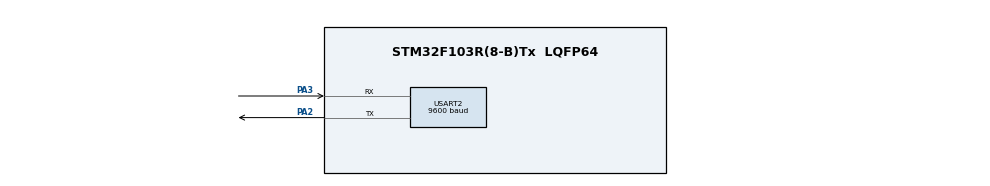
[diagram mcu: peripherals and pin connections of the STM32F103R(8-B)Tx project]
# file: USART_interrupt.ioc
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Mcu.Family=STM32F1
RCC.APB2Freq_Value=8000000
Mcu.Name=STM32F103R(8-B)Tx
PA2.Signal=USART2_TX
VP_SYS_VS_ND.Mode=No_Debug
NVIC.USART2_IRQn=true\:0\:0\:false\:false\:true\:true\:true
USART2.BaudRate=9600
Mcu.Package=LQFP64
ProjectManager.StackSize=0x400
USART2.VirtualMode=VM_ASYNC
PA3.Mode=Asynchronous
ProjectManager.HeapSize=0x200
ProjectManager.TargetToolchain=STM32CubeIDE
NVIC.PriorityGroup=NVIC_PRIORITYGROUP_4
PA2.Mode=Asynchronous
RCC.APB1Freq_Value=8000000
PA3.Signal=USART2_RX
board=custom

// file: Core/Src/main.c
/* USER CODE BEGIN Header */
/**
  ******************************************************************************
  * @file           : main.c
  * @brief          : Main program body
  ******************************************************************************
  * @attention
  *
  * <h2><center>&copy; Copyright (c) 2021 STMicroelectronics.
  * All rights reserved.</center></h2>
  *
  * This software component is licensed by ST under BSD 3-Clause license,
  * the "License"; You may not use this file except in compliance with the
  * License. You may obtain a copy of the License at:
  *                        opensource.org/licenses/BSD-3-Clause
  *
  ******************************************************************************
  */
/* USER CODE END Header */
#include "main.h"
#include "usart.h"
#include "gpio.h"

void SystemClock_Config(void);

/* USER CODE BEGIN 0 */
uint8_t rx_data = 0;

int _write(int file, char *ptr, int len)
{
	HAL_UART_Transmit(&huart2, (uint8_t *)ptr, (uint16_t)len, 0xFFFFFFFF);
	return (len);
}

int _read(int file, char *ptr, int len)
{
	HAL_UART_Receive(&huart2, (uint8_t *)ptr++, 1, 0xFFFFFFFF);
	return (1);
}

void HAL_UART_RxCpltCallback(UART_HandleTypeDef *huart)
{
	printf("rx data is %0x\r\n", rx_data);
	HAL_UART_Receive_IT(&huart2, &rx_data, 1);
}
/* USER CODE END 0 */

int main(void)
{

  /* MCU Configuration--------------------------------------------------------*/

  /* Reset of all peripherals, Initializes the Flash interface and the Systick. */
  HAL_Init();

  /* Configure the system clock */
  SystemClock_Config();

  /* Initialize all configured peripherals */
  MX_GPIO_Init();
  MX_USART2_UART_Init();
  /* USER CODE BEGIN 2 */
  printf("UART RX/TX Test Program\r\n");
  HAL_UART_Receive_IT(&huart2, &rx_data, 1);
  /* USER CODE END 2 */

  /* Infinite loop */
  while (1)
  {

  }
}

void SystemClock_Config(void)
{
  RCC_OscInitTypeDef RCC_OscInitStruct = {0};
  RCC_ClkInitTypeDef RCC_ClkInitStruct = {0};

  /** Initializes the RCC Oscillators according to the specified parameters
  * in the RCC_OscInitTypeDef structure.
  */
  RCC_OscInitStruct.OscillatorType = RCC_OSCILLATORTYPE_HSI;
  RCC_OscInitStruct.HSIState = RCC_HSI_ON;
  RCC_OscInitStruct.HSICalibrationValue = RCC_HSICALIBRATION_DEFAULT;
  RCC_OscInitStruct.PLL.PLLState = RCC_PLL_NONE;
  if (HAL_RCC_OscConfig(&RCC_OscInitStruct) != HAL_OK)
  {
    Error_Handler();
  }
  /** Initializes the CPU, AHB and APB buses clocks
  */
  RCC_ClkInitStruct.ClockType = RCC_CLOCKTYPE_HCLK|RCC_CLOCKTYPE_SYSCLK
                              |RCC_CLOCKTYPE_PCLK1|RCC_CLOCKTYPE_PCLK2;
  RCC_ClkInitStruct.SYSCLKSource = RCC_SYSCLKSOURCE_HSI;
  RCC_ClkInitStruct.AHBCLKDivider = RCC_SYSCLK_DIV1;
  RCC_ClkInitStruct.APB1CLKDivider = RCC_HCLK_DIV1;
  RCC_ClkInitStruct.APB2CLKDivider = RCC_HCLK_DIV1;

  if (HAL_RCC_ClockConfig(&RCC_ClkInitStruct, FLASH_LATENCY_0) != HAL_OK)
  {
    Error_Handler();
  }
}

void Error_Handler(void)
{
  __disable_irq();
  while (1)
  {
  }
}

/************************ (C) COPYRIGHT STMicroelectronics *****END OF FILE****/
